AUTOSAR XML (schema 4-2-1)
package /ComponentTypes
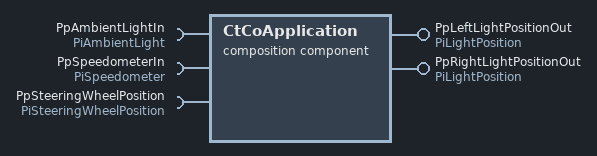
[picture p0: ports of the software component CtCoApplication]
  composition sw component type CtCoApplication
    provide port PpLeftLightPositionOut: provided-com-specs=[{data-element=DeLightLength, init-value=0}, {data-element=DeLightPosition, init-value=0}], provided-interface=PiLightPosition
    provide port PpRightLightPositionOut: provided-com-specs=[{data-element=DeLightLength, init-value=0}, {data-element=DeLightPosition, init-value=0}], provided-interface=PiLightPosition
    require port PpAmbientLightIn: nonqueued-receiver-com-spec{data-element=DeAmbientLight, filter=data-filter-type=ALWAYS, init-value=constant-reference=CDarkLight}, required-interface=PiAmbientLight
    require port PpSpeedometerIn: nonqueued-receiver-com-spec{data-element=DeSpeedometer, filter=data-filter-type=ALWAYS, init-value=constant-reference=CInitSpeed}, required-interface=PiSpeedometer
    require port PpSteeringWheelPosition: nonqueued-receiver-com-spec{data-element=DeSteeringWheelPosition, filter=data-filter-type=ALWAYS, init-value=constant-reference=CSteeringWheelInitPosition}, required-interface=PiSteeringWheelPosition
    8 x component:
      CpApAFSController: type=CtApAFSController
      CpApBatteryManager: type=CtApBatteryManager
      CpCddIoHwAb: type=CtCddIoHwAb
      CpSaAmbientLight: type=CtSaAmbientLight
      CpSaLeftFrontlight: type=CtSaFrontlight
      CpSaRightFrontlight: type=CtSaFrontlight
      CpSaSpeedometer: type=CtSaSpeedometer
      CpSaSteeringWheel: type=CtSaSteeringWheel
    connect CpApAFSController.PpLightPositionLeft -> CpSaLeftFrontlight.PpLightPositionIn
    connect CpApAFSController.PpLightPositionRight -> CpSaRightFrontlight.PpLightPositionIn
    connect CpApBatteryManager.PpBatteryMode -> CpApAFSController.PpBatteryMode
    connect CpApBatteryManager.PpBatteryMode -> CpSaAmbientLight.PpBatteryMode
    connect CpApBatteryManager.PpBatteryMode -> CpSaSpeedometer.PpBatteryMode
    connect CpApBatteryManager.PpBatteryMode -> CpSaSteeringWheel.PpBatteryMode
    connect CpCddIoHwAb.PpBatteryLevelHwAb -> CpApAFSController.PiBatteryLevelHwAb
    connect CpCddIoHwAb.PpAFSSwitch -> CpApAFSController.PpAFSSwitch
    connect CpCddIoHwAb.PpHighBeam -> CpApAFSController.PpHighBeam
    connect CpCddIoHwAb.PpBatteryLevelHwAb -> CpApBatteryManager.PiBatteryLevelHwAb
    connect CpSaAmbientLight.PpAmbientLightOut -> CpApAFSController.PpAmbientLight
    connect CpSaSpeedometer.PpSpeedometerOut -> CpApAFSController.PpSpeedometer
    connect CpSaSteeringWheel.PpSteeringWheelPositionOut -> CpApAFSController.PpSteeringWheelPosition
    delegate CpSaAmbientLight.PpAmbientLightIn <-> outer port PpAmbientLightIn
    delegate CpSaLeftFrontlight.PpLightPositionOut <-> outer port PpLeftLightPositionOut
    delegate CpSaRightFrontlight.PpLightPositionOut <-> outer port PpRightLightPositionOut
    delegate CpSaSpeedometer.PpSpeedometerIn <-> outer port PpSpeedometerIn
    delegate CpSaSteeringWheel.PpSteeringWheelPositionIn <-> outer port PpSteeringWheelPosition
